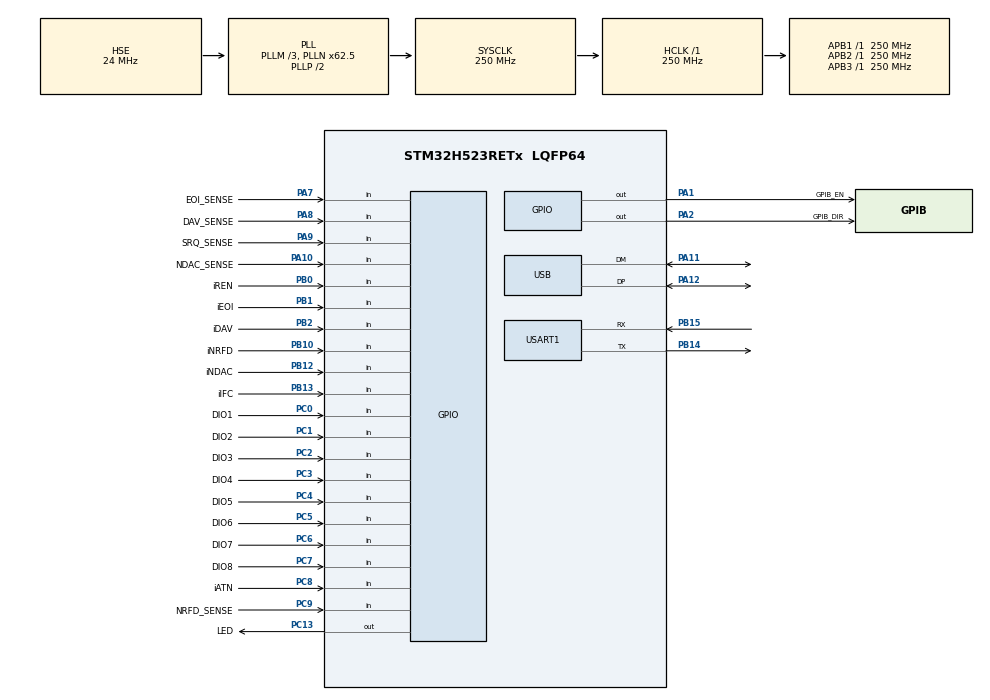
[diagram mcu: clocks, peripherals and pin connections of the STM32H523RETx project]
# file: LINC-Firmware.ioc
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BOOTPATH.BootPathName=LEGACY
BOOTPATH.UserSelectedBootPath=LEGACY
CORTEX_M33_NS.userName=CORTEX_M33
Mcu.Family=STM32H5
Mcu.Name=STM32H523RETx
Mcu.Package=LQFP64
NVIC.PriorityGroup=NVIC_PRIORITYGROUP_4
NVIC.TIM6_IRQn=true\:15\:0\:false\:false\:true\:false\:false\:true\:true
NVIC.TimeBase=TIM6_IRQn
NVIC.TimeBaseIP=TIM6
NVIC.USB_DRD_FS_IRQn=true\:0\:0\:false\:false\:true\:false\:true\:true\:true
PA1.GPIO_Label=GPIB_EN
PA1.Signal=GPIO_Output
PA10.GPIO_Label=NDAC_SENSE
PA10.Signal=GPIO_Input
PA11.Mode=Device
PA11.Signal=USB_DM
PA12.Mode=Device
PA12.Signal=USB_DP
PA13(JTMS/SWDIO).Mode=Trace_Asynchronous_SW
PA13(JTMS/SWDIO).Signal=DEBUG_JTMS-SWDIO
PA14(JTCK/SWCLK).Mode=Trace_Asynchronous_SW
PA14(JTCK/SWCLK).Signal=DEBUG_JTCK-SWCLK
PA2.GPIO_Label=GPIB_DIR
PA2.Signal=GPIO_Output
PA7.GPIO_Label=EOI_SENSE
PA7.Signal=GPIO_Input
PA8.GPIO_Label=DAV_SENSE
PA8.Signal=GPIO_Input
PA9.GPIO_Label=SRQ_SENSE
PA9.Signal=GPIO_Input
PB0.GPIO_Label=iREN
PB0.Signal=GPIO_Input
PB1.GPIO_Label=iEOI
PB1.Signal=GPIO_Input
PB10.GPIO_Label=iNRFD
PB10.Signal=GPIO_Input
PB12.GPIO_Label=iNDAC
PB12.Signal=GPIO_Input
PB13.GPIO_Label=iIFC
PB13.Signal=GPIO_Input
PB14.Mode=Asynchronous
PB14.Signal=USART1_TX
PB15.Mode=Asynchronous
PB15.Signal=USART1_RX
PB2.GPIO_Label=iDAV
PB2.Signal=GPIO_Input
PB3(JTDO/TRACESWO).Mode=Trace_Asynchronous_SW
PB3(JTDO/TRACESWO).Signal=DEBUG_JTDO-SWO
PC0.GPIO_Label=DIO1
PC0.Signal=GPIO_Input
PC1.GPIO_Label=DIO2
PC1.Signal=GPIO_Input
PC13.GPIO_Label=LED
PC13.Signal=GPIO_Output
PC14-OSC32_IN(OSC32_IN).Mode=LSE-External-Oscillator
PC14-OSC32_IN(OSC32_IN).Signal=RCC_OSC32_IN
PC15-OSC32_OUT(OSC32_OUT).Mode=LSE-External-Oscillator
PC15-OSC32_OUT(OSC32_OUT).Signal=RCC_OSC32_OUT
PC2.GPIO_Label=DIO3
PC2.Signal=GPIO_Input
PC3.GPIO_Label=DIO4
PC3.Signal=GPIO_Input
PC4.GPIO_Label=DIO5
PC4.Signal=GPIO_Input
PC5.GPIO_Label=DIO6
PC5.Signal=GPIO_Input
PC6.GPIO_Label=DIO7
PC6.Signal=GPIO_Input
PC7.GPIO_Label=DIO8
PC7.Signal=GPIO_Input
PC8.GPIO_Label=iATN
PC8.Signal=GPIO_Input
PC9.GPIO_Label=NRFD_SENSE
PC9.Signal=GPIO_Input
PH0-OSC_IN(PH0).Mode=HSE-External-Oscillator
PH0-OSC_IN(PH0).Signal=RCC_OSC_IN
PH1-OSC_OUT(PH1).Mode=HSE-External-Oscillator
PH1-OSC_OUT(PH1).Signal=RCC_OSC_OUT
ProjectManager.HeapSize=0x200
ProjectManager.StackSize=0x400
ProjectManager.TargetToolchain=CMake
RCC.ADCFreq_Value=250000000
RCC.AHBFreq_Value=250000000
RCC.APB1Freq_Value=250000000
RCC.APB1TimFreq_Value=250000000
RCC.APB2Freq_Value=250000000
RCC.APB2TimFreq_Value=250000000
RCC.APB3Freq_Value=250000000
RCC.CSI_VALUE=4000000
RCC.CortexFreq_Value=250000000
RCC.EPOD_VALUE=24000000
RCC.HCLKFreq_Value=250000000
RCC.HSE_VALUE=24000000
RCC.HSI48_VALUE=48000000
RCC.HSI_VALUE=64000000
RCC.LSIRC_VALUE=32000
RCC.PLLFRACN=4096
RCC.PLLM=3
RCC.PLLN=62
RCC.PLLSourceVirtual=RCC_PLL1_SOURCE_HSE
RCC.SYSCLKFreq_VALUE=250000000
RCC.SYSCLKSource=RCC_SYSCLKSOURCE_PLLCLK
RCC.USBFreq_Value=48000000
RCC.VCOOutputFreq_Value=500000000
THREADX.TX_APP_GENERATE_INIT_CODE=true
THREADX.TX_APP_MEM_POOL_SIZE=65536
TIM7.Prescaler=249
USART1.VirtualMode-Asynchronous=VM_ASYNC
USB.VirtualMode=Device_Only
USBX.BSP.number=1
USBX.Core_System=1
USBX.REG_UX_DEVICE_CORE=true
USBX.USBD_CDCACM_EPIN_ADDR=2
USBX.USBD_CDCACM_EPOUT_ADDR=3
USBX.USBD_MANUFACTURER_STRING=Husby Labs
USBX.USBD_PRODUCT_STRING=LINC
USBX.USBX_DEVICE_APP_THREAD_Size=1024
USBX.USBX_DEVICE_SYS_SIZE=10*1024
USBX.USBX_SYS_SIZE=15360
USBX.UX_APP_MEM_POOL_SIZE=20480
USBX.UX_DEVICE_APP_MEM_POOL_SIZE=15*1024
USBX.UX_DEVICE_CDC_ACM=1
USBX.UX_DEVICE_ENABLED_FS=1
USBX.UX_Device_Controller=1
USBX.UX_Device_CoreStack=1
USBX.UX_enabled_FS=1
USBX0.BSP.STBoard=false
USBX0.BSP.api=Unknown
USBX0.BSP.instance=USB
USBX0.BSP.ip=USB
USBX0.BSP.mode=Device_Only
USBX0.BSP.name=USB_Device
USBX0.BSP.solution=USB
VP_BOOTPATH_VS_BOOTPATH.Mode=BP_Activate
VP_CORTEX_M33_NS_VS_Hclk.Mode=Hclk_Mode
VP_ICACHE_VS_ICACHE.Mode=DirectMappedCache
VP_MEMORYMAP_VS_MEMORYMAP.Mode=CurAppReg
VP_PWR_VS_LPOM.Mode=PowerOptimisation
VP_PWR_VS_SECSignals.Mode=Security/Privilege
VP_RCC_USB.Mode=CRS SYNC Source USB
VP_SYS_VS_tim6.Mode=TIM6
VP_THREADX_VS_RTOSJjThreadXJjCoreJjDefault.Mode=Core_Default
VP_TIM7_VS_ClockSourceINT.Mode=Enable_Timer
VP_USBX_Core_System.Mode=Core_System
VP_USBX_UX\ Device\ CDC\ ACM\ Class_FS.Mode=UX_Device_class_CDC_ACM_FS_HS
VP_USBX_UX\ Device\ Controller_FS.Mode=UX_Device_Controller_FS
VP_USBX_UX\ Device\ CoreStack_FS.Mode=UX_Device_CoreStack
board=custom

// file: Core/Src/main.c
/* USER CODE BEGIN Header */
/**
  ******************************************************************************
  * @file           : main.c
  * @brief          : Main program body
  ******************************************************************************
  * @attention
  *
  * Copyright (c) 2026 STMicroelectronics.
  * All rights reserved.
  *
  * This software is licensed under terms that can be found in the LICENSE file
  * in the root directory of this software component.
  * If no LICENSE file comes with this software, it is provided AS-IS.
  *
  ******************************************************************************
  */
/* USER CODE END Header */
#include "app_threadx.h"
#include "main.h"

TIM_HandleTypeDef htim7;

UART_HandleTypeDef huart1;

PCD_HandleTypeDef hpcd_USB_DRD_FS;

void SystemClock_Config(void);
static void MX_GPIO_Init(void);
static void MX_USART1_UART_Init(void);
static void MX_ICACHE_Init(void);
static void MX_TIM7_Init(void);

/* USER CODE BEGIN 0 */
uint8_t payload[] = {0x00, 0x4A, 0xFF, 0xFF, 0xFF, 0xFF};
/* USER CODE END 0 */

int main(void)
{

  /* MCU Configuration--------------------------------------------------------*/

  /* Reset of all peripherals, Initializes the Flash interface and the Systick. */
  HAL_Init();

  /* Configure the system clock */
  SystemClock_Config();

  /* Initialize all configured peripherals */
  MX_GPIO_Init();
  MX_USART1_UART_Init();
  MX_ICACHE_Init();
  MX_TIM7_Init();
  /* USER CODE BEGIN 2 */
  // TODO: Remove debug safety block
  uint16_t i = 0;
  while (i < 15000) {
    HAL_GPIO_TogglePin(LED_GPIO_Port, LED_Pin);
    HAL_Delay(50);
    i += 50;
  }
  /* USER CODE END 2 */

  MX_ThreadX_Init();

  /* We should never get here as control is now taken by the scheduler */

  /* Infinite loop */
  while (1)
  {

  }
}

void SystemClock_Config(void)
{
  RCC_OscInitTypeDef RCC_OscInitStruct = {0};
  RCC_ClkInitTypeDef RCC_ClkInitStruct = {0};
  RCC_CRSInitTypeDef RCC_CRSInitStruct = {0};

  /** Configure the main internal regulator output voltage
  */
  __HAL_PWR_VOLTAGESCALING_CONFIG(PWR_REGULATOR_VOLTAGE_SCALE0);

  while(!__HAL_PWR_GET_FLAG(PWR_FLAG_VOSRDY)) {}

  /** Initializes the RCC Oscillators according to the specified parameters
  * in the RCC_OscInitTypeDef structure.
  */
  RCC_OscInitStruct.OscillatorType = RCC_OSCILLATORTYPE_HSI48|RCC_OSCILLATORTYPE_HSE;
  RCC_OscInitStruct.HSEState = RCC_HSE_ON;
  RCC_OscInitStruct.HSI48State = RCC_HSI48_ON;
  RCC_OscInitStruct.PLL.PLLState = RCC_PLL_ON;
  RCC_OscInitStruct.PLL.PLLSource = RCC_PLL1_SOURCE_HSE;
  RCC_OscInitStruct.PLL.PLLM = 3;
  RCC_OscInitStruct.PLL.PLLN = 62;
  RCC_OscInitStruct.PLL.PLLP = 2;
  RCC_OscInitStruct.PLL.PLLQ = 2;
  RCC_OscInitStruct.PLL.PLLR = 2;
  RCC_OscInitStruct.PLL.PLLRGE = RCC_PLL1_VCIRANGE_3;
  RCC_OscInitStruct.PLL.PLLVCOSEL = RCC_PLL1_VCORANGE_WIDE;
  RCC_OscInitStruct.PLL.PLLFRACN = 4096;
  if (HAL_RCC_OscConfig(&RCC_OscInitStruct) != HAL_OK)
  {
    Error_Handler();
  }

  /** Initializes the CPU, AHB and APB buses clocks
  */
  RCC_ClkInitStruct.ClockType = RCC_CLOCKTYPE_HCLK|RCC_CLOCKTYPE_SYSCLK
                              |RCC_CLOCKTYPE_PCLK1|RCC_CLOCKTYPE_PCLK2
                              |RCC_CLOCKTYPE_PCLK3;
  RCC_ClkInitStruct.SYSCLKSource = RCC_SYSCLKSOURCE_PLLCLK;
  RCC_ClkInitStruct.AHBCLKDivider = RCC_SYSCLK_DIV1;
  RCC_ClkInitStruct.APB1CLKDivider = RCC_HCLK_DIV1;
  RCC_ClkInitStruct.APB2CLKDivider = RCC_HCLK_DIV1;
  RCC_ClkInitStruct.APB3CLKDivider = RCC_HCLK_DIV1;

  if (HAL_RCC_ClockConfig(&RCC_ClkInitStruct, FLASH_LATENCY_5) != HAL_OK)
  {
    Error_Handler();
  }

  /** Enable the CRS APB clock
  */
  __HAL_RCC_CRS_CLK_ENABLE();

  /** Configures CRS
  */
  RCC_CRSInitStruct.Prescaler = RCC_CRS_SYNC_DIV1;
  RCC_CRSInitStruct.Source = RCC_CRS_SYNC_SOURCE_USB;
  RCC_CRSInitStruct.Polarity = RCC_CRS_SYNC_POLARITY_RISING;
  RCC_CRSInitStruct.ReloadValue = __HAL_RCC_CRS_RELOADVALUE_CALCULATE(48000000,1000);
  RCC_CRSInitStruct.ErrorLimitValue = 34;
  RCC_CRSInitStruct.HSI48CalibrationValue = 32;

  HAL_RCCEx_CRSConfig(&RCC_CRSInitStruct);

  /** Configure the programming delay
  */
  __HAL_FLASH_SET_PROGRAM_DELAY(FLASH_PROGRAMMING_DELAY_2);
}

static void MX_ICACHE_Init(void)
{

  /** Enable instruction cache in 1-way (direct mapped cache)
  */
  if (HAL_ICACHE_ConfigAssociativityMode(ICACHE_1WAY) != HAL_OK)
  {
    Error_Handler();
  }
  if (HAL_ICACHE_Enable() != HAL_OK)
  {
    Error_Handler();
  }

}

static void MX_TIM7_Init(void)
{

  TIM_MasterConfigTypeDef sMasterConfig = {0};

  htim7.Instance = TIM7;
  htim7.Init.Prescaler = 249;
  htim7.Init.CounterMode = TIM_COUNTERMODE_UP;
  htim7.Init.Period = 65535;
  htim7.Init.AutoReloadPreload = TIM_AUTORELOAD_PRELOAD_DISABLE;
  if (HAL_TIM_Base_Init(&htim7) != HAL_OK)
  {
    Error_Handler();
  }
  sMasterConfig.MasterOutputTrigger = TIM_TRGO_RESET;
  sMasterConfig.MasterSlaveMode = TIM_MASTERSLAVEMODE_DISABLE;
  if (HAL_TIMEx_MasterConfigSynchronization(&htim7, &sMasterConfig) != HAL_OK)
  {
    Error_Handler();
  }

}

static void MX_USART1_UART_Init(void)
{

  huart1.Instance = USART1;
  huart1.Init.BaudRate = 115200;
  huart1.Init.WordLength = UART_WORDLENGTH_8B;
  huart1.Init.StopBits = UART_STOPBITS_1;
  huart1.Init.Parity = UART_PARITY_NONE;
  huart1.Init.Mode = UART_MODE_TX_RX;
  huart1.Init.HwFlowCtl = UART_HWCONTROL_NONE;
  huart1.Init.OverSampling = UART_OVERSAMPLING_16;
  huart1.Init.OneBitSampling = UART_ONE_BIT_SAMPLE_DISABLE;
  huart1.Init.ClockPrescaler = UART_PRESCALER_DIV1;
  huart1.AdvancedInit.AdvFeatureInit = UART_ADVFEATURE_NO_INIT;
  if (HAL_UART_Init(&huart1) != HAL_OK)
  {
    Error_Handler();
  }
  if (HAL_UARTEx_SetTxFifoThreshold(&huart1, UART_TXFIFO_THRESHOLD_1_8) != HAL_OK)
  {
    Error_Handler();
  }
  if (HAL_UARTEx_SetRxFifoThreshold(&huart1, UART_RXFIFO_THRESHOLD_1_8) != HAL_OK)
  {
    Error_Handler();
  }
  if (HAL_UARTEx_DisableFifoMode(&huart1) != HAL_OK)
  {
    Error_Handler();
  }

}

void MX_USB_PCD_Init(void)
{

  hpcd_USB_DRD_FS.Instance = USB_DRD_FS;
  hpcd_USB_DRD_FS.Init.dev_endpoints = 8;
  hpcd_USB_DRD_FS.Init.speed = USBD_FS_SPEED;
  hpcd_USB_DRD_FS.Init.phy_itface = PCD_PHY_EMBEDDED;
  hpcd_USB_DRD_FS.Init.Sof_enable = DISABLE;
  hpcd_USB_DRD_FS.Init.low_power_enable = DISABLE;
  hpcd_USB_DRD_FS.Init.lpm_enable = DISABLE;
  hpcd_USB_DRD_FS.Init.battery_charging_enable = DISABLE;
  hpcd_USB_DRD_FS.Init.vbus_sensing_enable = DISABLE;
  hpcd_USB_DRD_FS.Init.bulk_doublebuffer_enable = DISABLE;
  hpcd_USB_DRD_FS.Init.iso_singlebuffer_enable = DISABLE;
  if (HAL_PCD_Init(&hpcd_USB_DRD_FS) != HAL_OK)
  {
    Error_Handler();
  }

}

static void MX_GPIO_Init(void)
{
  GPIO_InitTypeDef GPIO_InitStruct = {0};

  /* GPIO Ports Clock Enable */
  __HAL_RCC_GPIOC_CLK_ENABLE();
  __HAL_RCC_GPIOH_CLK_ENABLE();
  __HAL_RCC_GPIOA_CLK_ENABLE();
  __HAL_RCC_GPIOB_CLK_ENABLE();

  /*Configure GPIO pin Output Level */
  HAL_GPIO_WritePin(LED_GPIO_Port, LED_Pin, GPIO_PIN_RESET);

  /*Configure GPIO pin Output Level */
  HAL_GPIO_WritePin(GPIOA, GPIB_EN_Pin|GPIB_DIR_Pin, GPIO_PIN_RESET);

  /*Configure GPIO pin : LED_Pin */
  GPIO_InitStruct.Pin = LED_Pin;
  GPIO_InitStruct.Mode = GPIO_MODE_OUTPUT_PP;
  GPIO_InitStruct.Pull = GPIO_NOPULL;
  GPIO_InitStruct.Speed = GPIO_SPEED_FREQ_LOW;
  HAL_GPIO_Init(LED_GPIO_Port, &GPIO_InitStruct);

  /*Configure GPIO pins : DIO1_Pin DIO2_Pin DIO3_Pin DIO4_Pin
                           DIO5_Pin DIO6_Pin DIO7_Pin DIO8_Pin
                           iATN_Pin NRFD_SENSE_Pin */
  GPIO_InitStruct.Pin = DIO1_Pin|DIO2_Pin|DIO3_Pin|DIO4_Pin
                          |DIO5_Pin|DIO6_Pin|DIO7_Pin|DIO8_Pin
                          |iATN_Pin|NRFD_SENSE_Pin;
  GPIO_InitStruct.Mode = GPIO_MODE_INPUT;
  GPIO_InitStruct.Pull = GPIO_NOPULL;
  HAL_GPIO_Init(GPIOC, &GPIO_InitStruct);

  /*Configure GPIO pins : GPIB_EN_Pin GPIB_DIR_Pin */
  GPIO_InitStruct.Pin = GPIB_EN_Pin|GPIB_DIR_Pin;
  GPIO_InitStruct.Mode = GPIO_MODE_OUTPUT_PP;
  GPIO_InitStruct.Pull = GPIO_NOPULL;
  GPIO_InitStruct.Speed = GPIO_SPEED_FREQ_LOW;
  HAL_GPIO_Init(GPIOA, &GPIO_InitStruct);

  /*Configure GPIO pins : EOI_SENSE_Pin DAV_SENSE_Pin SRQ_SENSE_Pin NDAC_SENSE_Pin */
  GPIO_InitStruct.Pin = EOI_SENSE_Pin|DAV_SENSE_Pin|SRQ_SENSE_Pin|NDAC_SENSE_Pin;
  GPIO_InitStruct.Mode = GPIO_MODE_INPUT;
  GPIO_InitStruct.Pull = GPIO_NOPULL;
  HAL_GPIO_Init(GPIOA, &GPIO_InitStruct);

  /*Configure GPIO pins : iREN_Pin iEOI_Pin iDAV_Pin iNRFD_Pin
                           iNDAC_Pin iIFC_Pin */
  GPIO_InitStruct.Pin = iREN_Pin|iEOI_Pin|iDAV_Pin|iNRFD_Pin
                          |iNDAC_Pin|iIFC_Pin;
  GPIO_InitStruct.Mode = GPIO_MODE_INPUT;
  GPIO_InitStruct.Pull = GPIO_NOPULL;
  HAL_GPIO_Init(GPIOB, &GPIO_InitStruct);

}

void HAL_TIM_PeriodElapsedCallback(TIM_HandleTypeDef *htim)
{
  if (htim->Instance == TIM6)
  {
    HAL_IncTick();
  }
}

void Error_Handler(void)
{
  __disable_irq();
  while (1)
  {
  }
}
